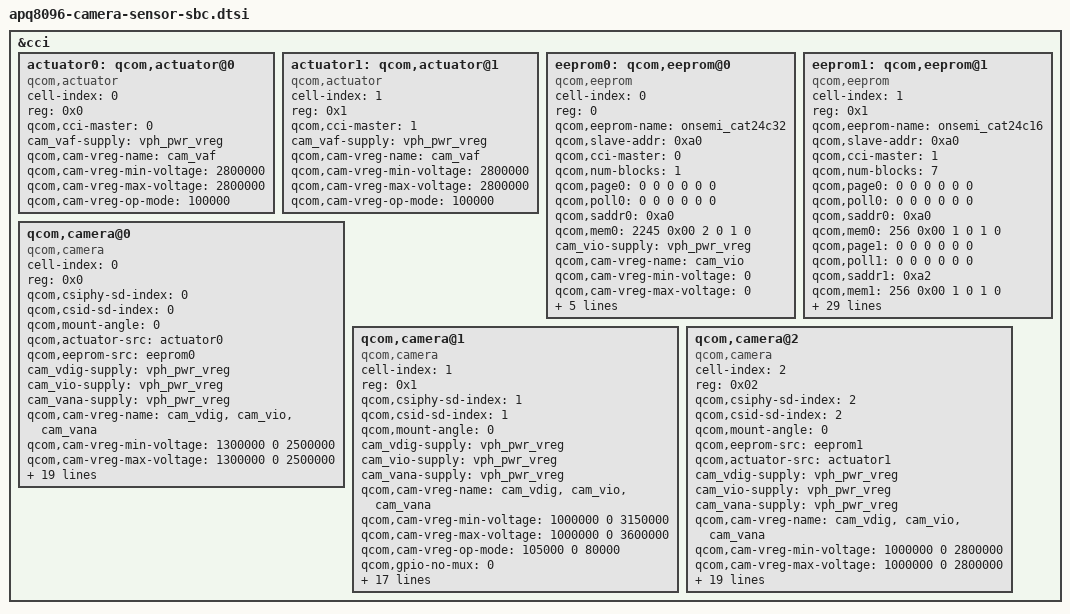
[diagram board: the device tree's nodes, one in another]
/*
 * Copyright (c) 2015-2016, The Linux Foundation. All rights reserved.
 *
 * This program is free software; you can redistribute it and/or modify
 * it under the terms of the GNU General Public License version 2 and
 * only version 2 as published by the Free Software Foundation.
 *
 * This program is distributed in the hope that it will be useful,
 * but WITHOUT ANY WARRANTY; without even the implied warranty of
 * MERCHANTABILITY or FITNESS FOR A PARTICULAR PURPOSE.  See the
 * GNU General Public License for more details.
 */

/*
 * Note: default configuration is for self-powered camera modules.
 */
&cci {
	actuator0: qcom,actuator@0 {
		cell-index = <0>;
		reg = <0x0>;
		compatible = "qcom,actuator";
		qcom,cci-master = <0>;
		cam_vaf-supply = <&vph_pwr_vreg>;
		qcom,cam-vreg-name = "cam_vaf";
		qcom,cam-vreg-min-voltage = <2800000>;
		qcom,cam-vreg-max-voltage = <2800000>;
		qcom,cam-vreg-op-mode = <100000>;
	};

	actuator1: qcom,actuator@1 {
		cell-index = <1>;
		reg = <0x1>;
		compatible = "qcom,actuator";
		qcom,cci-master = <1>;
		cam_vaf-supply = <&vph_pwr_vreg>;
		qcom,cam-vreg-name = "cam_vaf";
		qcom,cam-vreg-min-voltage = <2800000>;
		qcom,cam-vreg-max-voltage = <2800000>;
		qcom,cam-vreg-op-mode = <100000>;
	};

	eeprom0: qcom,eeprom@0 {
		cell-index = <0>;
		reg = <0>;
		qcom,eeprom-name = "onsemi_cat24c32";
		compatible = "qcom,eeprom";
		qcom,slave-addr = <0xa0>;
		qcom,cci-master = <0>;
		qcom,num-blocks = <1>;
		qcom,page0 = <0 0 0 0 0 0>;
		qcom,poll0 = <0 0 0 0 0 0>;
		qcom,saddr0 = <0xa0>;
		qcom,mem0 = <2245 0x00 2 0 1 0>;
		cam_vio-supply = <&vph_pwr_vreg>;
		qcom,cam-vreg-name = "cam_vio";
		qcom,cam-vreg-min-voltage = <0>;
		qcom,cam-vreg-max-voltage = <0>;
		qcom,cam-vreg-op-mode = <0>;
		qcom,cam-power-seq-type = "sensor_vreg";
		qcom,cam-power-seq-val = "cam_vio";
		qcom,cam-power-seq-cfg-val = <1>;
		qcom,cam-power-seq-delay = <1>;
	};

	eeprom1: qcom,eeprom@1 {
		cell-index = <1>;
		reg = <0x1>;
		qcom,eeprom-name = "onsemi_cat24c16";
		compatible = "qcom,eeprom";
		qcom,slave-addr = <0xa0>;
		qcom,cci-master = <1>;
		qcom,num-blocks = <7>;

		qcom,page0 = <0 0 0 0 0 0>;
		qcom,poll0 = <0 0 0 0 0 0>;
		qcom,saddr0 = <0xa0>;
		qcom,mem0 = <256 0x00 1 0 1 0>;

		qcom,page1 = <0 0 0 0 0 0>;
		qcom,poll1 = <0 0 0 0 0 0>;
		qcom,saddr1 = <0xa2>;
		qcom,mem1 = <256 0x00 1 0 1 0>;

		qcom,page2 = <0 0 0 0 0 0>;
		qcom,poll2 = <0 0 0 0 0 0>;
		qcom,saddr2 = <0xa4>;
		qcom,mem2 = <256 0x00 1 0 1 0>;

		qcom,page3 = <0 0 0 0 0 0>;
		qcom,poll3 = <0 0 0 0 0 0>;
		qcom,saddr3 = <0xa6>;
		qcom,mem3 = <256 0x00 1 0 1 0>;

		qcom,page4 = <0 0 0 0 0 0>;
		qcom,poll4 = <0 0 0 0 0 0>;
		qcom,saddr4 = <0xa8>;
		qcom,mem4 = <256 0x00 1 0 1 0>;

		qcom,page5 = <0 0 0 0 0 0>;
		qcom,poll5 = <0 0 0 0 0 0>;
		qcom,saddr5 = <0xaa>;
		qcom,mem5 = <256 0x00 1 0 1 0>;

		qcom,page6 = <0 0 0 0 0 0>;
		qcom,poll6 = <0 0 0 0 0 0>;
		qcom,saddr6 = <0xac>;
		qcom,mem6 = <254 0x00 1 0 1 0>;

		cam_vio-supply = <&vph_pwr_vreg>;
		qcom,cam-vreg-name = "cam_vio";
		qcom,cam-vreg-min-voltage = <0>;
		qcom,cam-vreg-max-voltage = <0>;
		qcom,cam-vreg-op-mode = <0>;
		qcom,cam-power-seq-type = "sensor_vreg";
		qcom,cam-power-seq-val = "cam_vio";
		qcom,cam-power-seq-cfg-val = <1>;
		qcom,cam-power-seq-delay = <1>;
	};

	qcom,camera@0 {
		cell-index = <0>;
		compatible = "qcom,camera";
		reg = <0x0>;
		qcom,csiphy-sd-index = <0>;
		qcom,csid-sd-index = <0>;
		qcom,mount-angle = <0>;
		qcom,actuator-src = <&actuator0>;
		qcom,eeprom-src = <&eeprom0>;
		cam_vdig-supply = <&vph_pwr_vreg>;
		cam_vio-supply = <&vph_pwr_vreg>;
		cam_vana-supply = <&vph_pwr_vreg>;
		qcom,cam-vreg-name = "cam_vdig", "cam_vio", "cam_vana";
		qcom,cam-vreg-min-voltage = <1300000 0 2500000>;
		qcom,cam-vreg-max-voltage = <1300000 0 2500000>;
		qcom,cam-vreg-op-mode = <105000 0 80000>;
		qcom,gpio-no-mux = <0>;
		pinctrl-names = "cam_default", "cam_suspend";
		pinctrl-0 = <&cam_sensor_mclk0_active &cam_csi0_sensor_active>;
		pinctrl-1 = <&cam_sensor_mclk0_suspend
				&cam_csi0_sensor_suspend>;
		gpios = <&tlmm 13 0>,
			<&tlmm 25 0>,
			<&tlmm 26 0>;
		qcom,gpio-reset = <1>;
		qcom,gpio-standby = <2>;
		qcom,gpio-req-tbl-num = <0 1 2>;
		qcom,gpio-req-tbl-flags = <1 0 0>;
		qcom,gpio-req-tbl-label = "CAMIF_MCLK0",
					  "CAM_RESET0",
					  "CAM_STANDBY0";
		qcom,sensor-position = <0>;
		qcom,sensor-mode = <0>;
		qcom,cci-master = <0>;
		status = "ok";
		clocks = <&clock_mmss clk_mclk0_clk_src>,
				<&clock_mmss clk_camss_mclk0_clk>;
		clock-names = "cam_src_clk", "cam_clk";
		qcom,clock-rates = <24000000 0>;
	};

	qcom,camera@1 {
		cell-index = <1>;
		compatible = "qcom,camera";
		reg = <0x1>;
		qcom,csiphy-sd-index = <1>;
		qcom,csid-sd-index = <1>;
		qcom,mount-angle = <0>;
		cam_vdig-supply = <&vph_pwr_vreg>;
		cam_vio-supply = <&vph_pwr_vreg>;
		cam_vana-supply = <&vph_pwr_vreg>;
		qcom,cam-vreg-name = "cam_vdig", "cam_vio", "cam_vana";
		qcom,cam-vreg-min-voltage = <1000000 0 3150000>;
		qcom,cam-vreg-max-voltage = <1000000 0 3600000>;
		qcom,cam-vreg-op-mode = <105000 0 80000>;
		qcom,gpio-no-mux = <0>;
		pinctrl-names = "cam_default", "cam_suspend";
		pinctrl-0 = <&cam_sensor_mclk1_active &cam_csi1_sensor_active>;
		pinctrl-1 = <&cam_sensor_mclk1_suspend
				&cam_csi1_sensor_suspend>;
		gpios = <&tlmm 14 0>,
			<&tlmm 104 0>,
			<&tlmm 98 0>;
		qcom,gpio-reset = <1>;
		qcom,gpio-standby = <2>;
		qcom,gpio-req-tbl-num = <0 1 2>;
		qcom,gpio-req-tbl-flags = <1 0 0>;
		qcom,gpio-req-tbl-label = "CAMIF_MCLK1",
					  "CAM_RESET1",
					  "CAM_STANDBY1";
		qcom,sensor-position = <0>;
		qcom,sensor-mode = <0>;
		qcom,cci-master = <0>;
		status = "ok";
		clocks = <&clock_mmss clk_mclk1_clk_src>,
			<&clock_mmss clk_camss_mclk1_clk>;
		clock-names = "cam_src_clk", "cam_clk";
		qcom,clock-rates = <24000000 0>;
	};

	qcom,camera@2 {
		cell-index = <2>;
		compatible = "qcom,camera";
		reg = <0x02>;
		qcom,csiphy-sd-index = <2>;
		qcom,csid-sd-index = <2>;
		qcom,mount-angle = <0>;
		qcom,eeprom-src = <&eeprom1>;
		qcom,actuator-src = <&actuator1>;
		cam_vdig-supply = <&vph_pwr_vreg>;
		cam_vio-supply = <&vph_pwr_vreg>;
		cam_vana-supply = <&vph_pwr_vreg>;
		qcom,cam-vreg-name = "cam_vdig", "cam_vio", "cam_vana";
		qcom,cam-vreg-min-voltage = <1000000 0 2800000>;
		qcom,cam-vreg-max-voltage = <1000000 0 2800000>;
		qcom,cam-vreg-op-mode = <105000 0 80000>;
		qcom,gpio-no-mux = <0>;
		pinctrl-names = "cam_default", "cam_suspend";
		pinctrl-0 = <&cam_sensor_mclk2_active &cam_csi2_sensor_active>;
		pinctrl-1 = <&cam_sensor_mclk2_suspend
				&cam_csi2_sensor_suspend>;
		gpios = <&tlmm 15 0>,
			<&tlmm 23 0>,
			<&tlmm 133 0>;
		qcom,gpio-reset = <1>;
		qcom,gpio-standby = <2>;
		qcom,gpio-req-tbl-num = <0 1 2>;
		qcom,gpio-req-tbl-flags = <1 0 0>;
		qcom,gpio-req-tbl-label = "CAMIF_MCLK2",
					  "CAM_RESET2",
					  "CAM_STANDBY2";
		qcom,sensor-position = <1>;
		qcom,sensor-mode = <0>;
		qcom,cci-master = <1>;
		status = "ok";
		clocks = <&clock_mmss clk_mclk2_clk_src>,
			<&clock_mmss clk_camss_mclk2_clk>;
		clock-names = "cam_src_clk", "cam_clk";
		qcom,clock-rates = <24000000 0>;
	};
};
